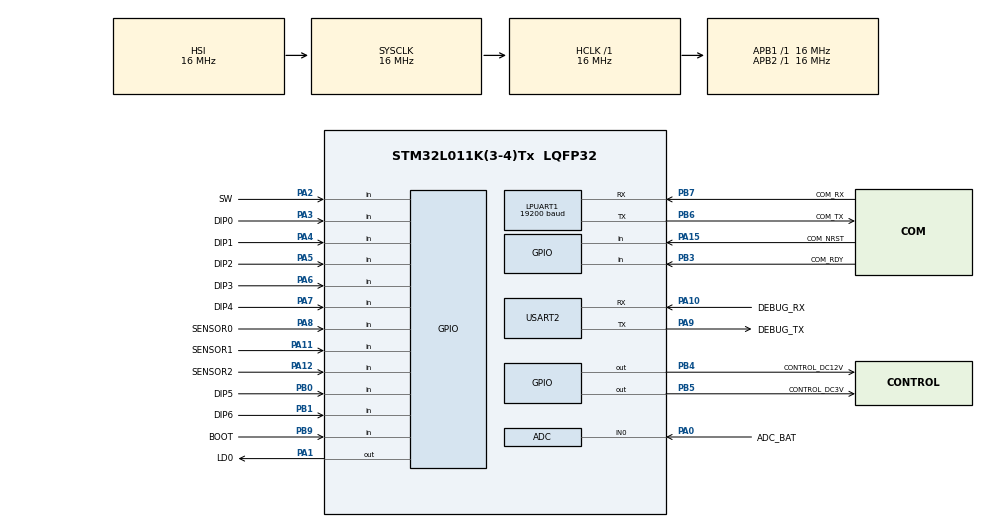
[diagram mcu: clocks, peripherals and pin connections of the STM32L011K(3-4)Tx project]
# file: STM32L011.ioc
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Dma.LPUART1_RX.0.Direction=DMA_PERIPH_TO_MEMORY
Dma.LPUART1_RX.0.Instance=DMA1_Channel3
Dma.LPUART1_RX.0.MemDataAlignment=DMA_MDATAALIGN_BYTE
Dma.LPUART1_RX.0.MemInc=DMA_MINC_ENABLE
Dma.LPUART1_RX.0.Mode=DMA_CIRCULAR
Dma.LPUART1_RX.0.PeriphDataAlignment=DMA_PDATAALIGN_BYTE
Dma.LPUART1_RX.0.PeriphInc=DMA_PINC_DISABLE
Dma.LPUART1_RX.0.Priority=DMA_PRIORITY_LOW
Dma.Request0=LPUART1_RX
Dma.Request1=USART2_RX
Dma.USART2_RX.1.Direction=DMA_PERIPH_TO_MEMORY
Dma.USART2_RX.1.Instance=DMA1_Channel5
Dma.USART2_RX.1.MemDataAlignment=DMA_MDATAALIGN_BYTE
Dma.USART2_RX.1.MemInc=DMA_MINC_ENABLE
Dma.USART2_RX.1.Mode=DMA_CIRCULAR
Dma.USART2_RX.1.PeriphDataAlignment=DMA_PDATAALIGN_BYTE
Dma.USART2_RX.1.PeriphInc=DMA_PINC_DISABLE
Dma.USART2_RX.1.Priority=DMA_PRIORITY_LOW
LPUART1.BaudRate=19200
LPUART1.WordLength=UART_WORDLENGTH_8B
Mcu.Family=STM32L0
Mcu.Name=STM32L011K(3-4)Tx
Mcu.Package=LQFP32
NVIC.DMA1_Channel2_3_IRQn=true\:0\:0\:false\:false\:true\:false\:true
NVIC.DMA1_Channel4_5_IRQn=true\:0\:0\:false\:false\:true\:false\:true
NVIC.LPUART1_IRQn=true\:0\:0\:false\:false\:true\:true\:true
NVIC.RTC_IRQn=true\:0\:0\:false\:false\:true\:true\:true
PA0-CK_IN.GPIO_Label=ADC_BAT
PA0-CK_IN.Mode=IN0
PA0-CK_IN.Signal=ADC_IN0
PA1.GPIO_Label=LD0
PA1.Signal=GPIO_Output
PA10.GPIO_Label=DEBUG_RX
PA10.Mode=Asynchronous
PA10.Signal=USART2_RX
PA11.GPIO_Label=SENSOR1
PA11.Signal=GPIO_Input
PA12.GPIO_Label=SENSOR2
PA12.Signal=GPIO_Input
PA13.GPIO_Label=SWDIO
PA13.Mode=Serial_Wire
PA13.Signal=SYS_SWDIO
PA14.GPIO_Label=SWCLK
PA14.Mode=Serial_Wire
PA14.Signal=SYS_SWCLK
PA15.GPIO_Label=COM_NRST
PA15.Signal=GPIO_Input
PA2.GPIO_Label=SW
PA2.Signal=GPIO_Input
PA3.GPIO_Label=DIP0
PA3.Signal=GPIO_Input
PA4.GPIO_Label=DIP1
PA4.Signal=GPIO_Input
PA5.GPIO_Label=DIP2
PA5.Signal=GPIO_Input
PA6.GPIO_Label=DIP3
PA6.Signal=GPIO_Input
PA7.GPIO_Label=DIP4
PA7.Signal=GPIO_Input
PA8.GPIO_Label=SENSOR0
PA8.Signal=GPIO_Input
PA9.GPIO_Label=DEBUG_TX
PA9.Mode=Asynchronous
PA9.Signal=USART2_TX
PB0.GPIO_Label=DIP5
PB0.Signal=GPIO_Input
PB1.GPIO_Label=DIP6
PB1.Signal=GPIO_Input
PB3.GPIO_Label=COM_RDY
PB3.Signal=GPIO_Input
PB4.GPIO_Label=CONTROL_DC12V
PB4.Signal=GPIO_Output
PB5.GPIO_Label=CONTROL_DC3V
PB5.Signal=GPIO_Output
PB6.GPIO_Label=COM_TX
PB6.Mode=Asynchronous
PB6.Signal=LPUART1_TX
PB7.GPIO_Label=COM_RX
PB7.Mode=Asynchronous
PB7.Signal=LPUART1_RX
PB9-BOOT0.GPIO_Label=BOOT
PB9-BOOT0.Signal=GPIO_Input
PC14-OSC32_IN.GPIO_Label=OSC_IN
PC14-OSC32_IN.Mode=LSE-External-Oscillator
PC14-OSC32_IN.Signal=RCC_OSC32_IN
PC15-OSC32_OUT.GPIO_Label=OSC_OUT
PC15-OSC32_OUT.Mode=LSE-External-Oscillator
PC15-OSC32_OUT.Signal=RCC_OSC32_OUT
ProjectManager.HeapSize=0x200
ProjectManager.StackSize=0x400
ProjectManager.TargetToolchain=EWARM V8.32
RCC.AHBFreq_Value=16000000
RCC.APB1Freq_Value=16000000
RCC.APB1TimFreq_Value=16000000
RCC.APB2Freq_Value=16000000
RCC.APB2TimFreq_Value=16000000
RCC.HCLKFreq_Value=16000000
RCC.HSE_VALUE=8000000
RCC.HSI16_VALUE=16000000
RCC.HSI48_VALUE=48000000
RCC.HSI_VALUE=16000000
RCC.MSI_VALUE=2097000
RCC.PLLDIV=RCC_PLLDIV_3
RCC.RTCClockSelection=RCC_RTCCLKSOURCE_LSE
RCC.RTCClockSelectionVirtual=RCC_RTCCLKSOURCE_LSE
RCC.SYSCLKFreq_VALUE=16000000
RCC.SYSCLKSource=RCC_SYSCLKSOURCE_HSI
RCC.VCOOutputFreq_Value=48000000
RTC.WakeUpClock-WakeUp=RTC_WAKEUPCLOCK_CK_SPRE_16BITS
RTC.WakeUpCounter-WakeUp=65535
USART2.VirtualMode-Asynchronous=VM_ASYNC
VP_RTC_VS_RTC_Activate.Mode=RTC_Enabled
VP_RTC_VS_RTC_WakeUp_intern.Mode=WakeUp
board=NUCLEO-L011K4

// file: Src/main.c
/* USER CODE BEGIN Header */
/**
  ******************************************************************************
  * @file           : main.c
  * @brief          : Main program body
  ******************************************************************************
  * @attention
  *
  * <h2><center>&copy; Copyright (c) 2019 STMicroelectronics.
  * All rights reserved.</center></h2>
  *
  * This software component is licensed by ST under BSD 3-Clause license,
  * the "License"; You may not use this file except in compliance with the
  * License. You may obtain a copy of the License at:
  *                        opensource.org/licenses/BSD-3-Clause
  *
  ******************************************************************************
  */
/* USER CODE END Header */

#include "main.h"
#include "adc.h"
#include "dma.h"
#include "usart.h"
#include "rtc.h"
#include "gpio.h"

/* USER CODE BEGIN Includes */
#include "lpsb.h"

/* USER CODE END Includes */

void SystemClock_Config(void);

int main(void)
{

  /* MCU Configuration--------------------------------------------------------*/

  /* Reset of all peripherals, Initializes the Flash interface and the Systick. */
  HAL_Init();

  /* Configure the system clock */
  SystemClock_Config();

  /* Initialize all configured peripherals */
  MX_GPIO_Init();
  MX_DMA_Init();
  MX_USART2_UART_Init();
  MX_LPUART1_UART_Init();
  MX_RTC_Init();
  MX_ADC_Init();
  /* USER CODE BEGIN 2 */
  lpsb_start();
  /* USER CODE END 2 */

  /* Infinite loop */
  /* USER CODE BEGIN WHILE */
  while (1)
  {
    lpsb_while();
    /* USER CODE END WHILE */

  }
}

void SystemClock_Config(void)
{
  RCC_OscInitTypeDef RCC_OscInitStruct = {0};
  RCC_ClkInitTypeDef RCC_ClkInitStruct = {0};
  RCC_PeriphCLKInitTypeDef PeriphClkInit = {0};

  /** Configure the main internal regulator output voltage
  */
  __HAL_PWR_VOLTAGESCALING_CONFIG(PWR_REGULATOR_VOLTAGE_SCALE1);
  /** Configure LSE Drive Capability
  */
  HAL_PWR_EnableBkUpAccess();
  __HAL_RCC_LSEDRIVE_CONFIG(RCC_LSEDRIVE_LOW);
  /** Initializes the CPU, AHB and APB busses clocks
  */
  RCC_OscInitStruct.OscillatorType = RCC_OSCILLATORTYPE_HSI|RCC_OSCILLATORTYPE_LSE;
  RCC_OscInitStruct.LSEState = RCC_LSE_ON;
  RCC_OscInitStruct.HSIState = RCC_HSI_ON;
  RCC_OscInitStruct.HSICalibrationValue = RCC_HSICALIBRATION_DEFAULT;
  RCC_OscInitStruct.PLL.PLLState = RCC_PLL_NONE;
  if (HAL_RCC_OscConfig(&RCC_OscInitStruct) != HAL_OK)
  {
    Error_Handler();
  }
  /** Initializes the CPU, AHB and APB busses clocks
  */
  RCC_ClkInitStruct.ClockType = RCC_CLOCKTYPE_HCLK|RCC_CLOCKTYPE_SYSCLK
                              |RCC_CLOCKTYPE_PCLK1|RCC_CLOCKTYPE_PCLK2;
  RCC_ClkInitStruct.SYSCLKSource = RCC_SYSCLKSOURCE_HSI;
  RCC_ClkInitStruct.AHBCLKDivider = RCC_SYSCLK_DIV1;
  RCC_ClkInitStruct.APB1CLKDivider = RCC_HCLK_DIV1;
  RCC_ClkInitStruct.APB2CLKDivider = RCC_HCLK_DIV1;

  if (HAL_RCC_ClockConfig(&RCC_ClkInitStruct, FLASH_LATENCY_0) != HAL_OK)
  {
    Error_Handler();
  }
  PeriphClkInit.PeriphClockSelection = RCC_PERIPHCLK_USART2|RCC_PERIPHCLK_LPUART1
                              |RCC_PERIPHCLK_RTC;
  PeriphClkInit.Usart2ClockSelection = RCC_USART2CLKSOURCE_PCLK1;
  PeriphClkInit.Lpuart1ClockSelection = RCC_LPUART1CLKSOURCE_PCLK1;
  PeriphClkInit.RTCClockSelection = RCC_RTCCLKSOURCE_LSE;
  if (HAL_RCCEx_PeriphCLKConfig(&PeriphClkInit) != HAL_OK)
  {
    Error_Handler();
  }
}

void Error_Handler(void)
{
}

/************************ (C) COPYRIGHT STMicroelectronics *****END OF FILE****/
